# DEBUGSS_WRAP0_CSCTI1 register map
Vendor: Texas Instruments
Peripheral module from a debugger description file (folder am62P).
Registers are 32-bit, access per field, reset 0x0 unless marked. A register's access mark holds for its fields unless they carry their own. Offsets are as the file gives them; lines under a group give offsets from that group; [hi:lo] are bit positions; {n}, {i} and the like mark numbered series; 'fields as' and 'values as' point back to an identical list; <NAME> marks a mode.

## DEBUGSS_WRAP0_CSCTI1
0x00 CSCTI_CFG_1_CTICONTROL — CTI Control Register.
  [0] GLBEN rw — Enables or disables the Embedded Cross Trigger, 1=enabled
0x10 CSCTI_CFG_1_CTIINTACK — CTI Interrupt Acknowledge Register.
  [7:0] INTACK rw — Acknowledges the corresponding CTITRIGOUT output Write 1 = CTITRIGOUT is acknowledged and is cleared when MAPTRIGOUT is LOW There is one bit of the register for each CTITRIGOUT output
0x14 CSCTI_CFG_1_CTIAPPSET — CTI Application Trigger Set Register.
  [3:0] APPSET rw — The CTI Application Trigger Set Register is read/write A write to this register causes a channel event to be raised, corresponding to the bit written to
0x18 CSCTI_CFG_1_CTIAPPCLEAR — CTI Application Trigger Clear Register.
  [3:0] APPCLR rw — The CTI Application Trigger Clear Register is write-only A write to this register causes a channel event to be cleared, corresponding to the bit written to
0x1C CSCTI_CFG_1_CTIAPPPULSE — CTI Application Trigger Pulse Register.
  [3:0] APPPULSE rw — The CTI Application Pulse Register is write-only A write to this register causes a channel event pulse, one CTICLK period, to be generated, corresponding to the bit written to This register clears itself immediately
0x20 CSCTI_CFG_1_CTIINEN0 — CTI Application Trigger to Channel Enable Register 0
  [3:0] TRIGINEN rw — The CTI Trigger to Channel Enable Registers enable the signalling of an event on CTM channels when the core issues a trigger, CTITRIGIN, to the CTI There is one register for each of the eight CTITRIGIN inputs Within each register there is one bit for each of the four channels implemented These registers do not affect the application trigger operations
0x24 CSCTI_CFG_1_CTIINEN1 — CTI Application Trigger to Channel Enable Register 1
  [2:0] TRIGINEN rw — The CTI Trigger to Channel Enable Registers enable the signalling of an event on CTM channels when the core issues a trigger, CTITRIGIN, to the CTI There is one register for each of the eight CTITRIGIN inputs Within each register there is one bit for each of the four channels implemented These registers do not affect the application trigger operations
{0x20+4i} CSCTI_CFG_1_CTIINEN{i} (i=2..7) — CTI Application Trigger to Channel Enable Register {i}
  fields as CSCTI_CFG_1_CTIINEN0
{0xA0+4i} CSCTI_CFG_1_CTIOUTEN{i} (i=0..7) — CTI Channel to Trigger Enable Register {i}
  [3:0] TRIGOUTEN rw — The CTI Channel to Trigger Enable Registers define which channels can generate a CTITRIGOUT output There is one register for each of the eight CTITRIGOUT outputs Within each register there is one bit for each of the four channels implemented These registers affect the mapping from application trigger to trigger outputs
0x130 CSCTI_CFG_1_CTITRIGINSTATUS ro — CTI Trigger In Status Register
  [7:0] TRIGINSTATUS — Shows the status of the CTITRIGIN inputs: 1=CTITRIGIN is active, 0=CTITRIGIN is inactive
0x134 CSCTI_CFG_1_CTITRIGOUTSTATUS ro — CTI Trigger Out Status Register
  [7:0] TRIGOUTSTATUS — Shows the status of the CTITRIGOUT outputs: 1=CTITRIGOUT is active, 0=CTITRIGOUT is inactive
0x138 CSCTI_CFG_1_CTICHINSTATUS ro — CTI Channel In Status Register
  [3:0] CHINSTATUS — Shows the status of the CTICHIN inputs: 1=CTICHIN is active, 0=CTICHIN is inactive
0x13C CSCTI_CFG_1_CTICHOUTSTATUS ro — CTI Channel Out Status Register
  [3:0] CHOUTSTATUS — Shows the status of the CTICHOUT outputs: 1=CTICHOUT is active, 0=CTICHOUT is inactive
0x140 CSCTI_CFG_1_CTIGATE ro — The Gate Enable Register prevents the channels from propagating through the CTM to other CTIs.
  [3:0] CTIGATEEN — Gate enable for the four channels [1 per bit]
0x144 CSCTI_CFG_1_ASICCTL — Allows external multiplexing of the trigger signals
  [7:0] ASICCTL rw — Implementation-defined ASIC control, value written to the register is output on ASICCTL[7:0]
0xEDC CSCTI_CFG_1_ITCHINACK — Integration and Test register
  [3:0] CTCHINACK rw — Sets the value of the CTCHINACK outputs
0xEE0 CSCTI_CFG_1_ITTRIGINACK — ITTRIGINACK Register
  [7:0] CTTRIGINACK rw — Sets the value of the CTTRIGINACK outputs
0xEE4 CSCTI_CFG_1_ITCHOUT — ITCHOUT Register
  [3:0] CTCHOUT rw — Sets the value of the CTCHOUT outputs
0xEE8 CSCTI_CFG_1_ITTRIGOUT — ITTRIGOUT Register
  [7:0] CTTRIGOUT rw — Sets the value of the CTTRIGOUT outputs
0xEEC CSCTI_CFG_1_ITCHOUTACK — ITCHOUTACK Register
  [7:0] CTCHOUTACK rw — Sets the value of the CTCHOUTACK outputs
0xEF0 CSCTI_CFG_1_ITTRIGOUTACK ro — ITTRIGOUTACK Register
  [7:0] CTTRIGOUTACK — Reads the value of the CTTRIGOUTACK inputs
0xEF4 CSCTI_CFG_1_ITCHIN ro — ITCHIN Register
  [3:0] CTCHIN — Reads the value of the CTCHIN inputs
0xEF8 CSCTI_CFG_1_ITTRIGIN ro — ITTRIGIN Register
  [7:0] CTTRIGIN — Reads the value of the CTTRIGIN inputs
0xF00 CSCTI_CFG_1_ITCTRL — ITCTRL Register
  [0] ITEN rw — Integration Test control enable
0xFA0 CSCTI_CFG_1_CTSET — Claim Tag Set Register
  [3:0] CLAIM_TAG_SET rw
0xFA4 CSCTI_CFG_1_CTCLR — Claim Tag Clear Register
  [3:0] CLAIM_TAG_CLEAR rw
0xFB0 CSCTI_CFG_1_LAREG rw — Software must write 0xC5ACCE55 to this register in order for application to gain access to the other registers. If paddrdbg31 is high, this is ignored.
  [31:0] LOCKACCESSREG — Software must write 0xC5ACCE55 to this register in order for application to gain access to the other registers If paddrdbg31 is high, this is ignored
0xFB4 CSCTI_CFG_1_LSREG ro — The CTI implements two memory maps controlled through PADDRDBG31. When PADDRDBG31 is HIGH, the Lock Status Register reads as 0x0 indicating that no lock exists. When PADDRDBG31 is LOW, the Lock Status Register reads as 0x3 from reset. This indicates a 32-bit lock access mechanism is present and is locked
  [1:0] LOCK_STATUS — The CTI implements two memory maps controlled through PADDRDBG31 When PADDRDBG31 is HIGH, the Lock Status Register reads as 0x0 indicating that no lock exists When PADDRDBG31 is LOW, the Lock Status Register reads as 0x3 from reset This indicates a 32-bit lock access mechanism is present and is locked Application must write to the LAREG to gain access
0xFB8 CSCTI_CFG_1_AUTHST ro — Reports the required security level.
  [3:0] AUTHENTICATION_STATUS — Reports the required security level bit 0 indicates Invasive Debug Controlled and bit 1 is the current value Bit 2 indicates non-invasive debug controlled and bit 3 is the current value Returns 0x5
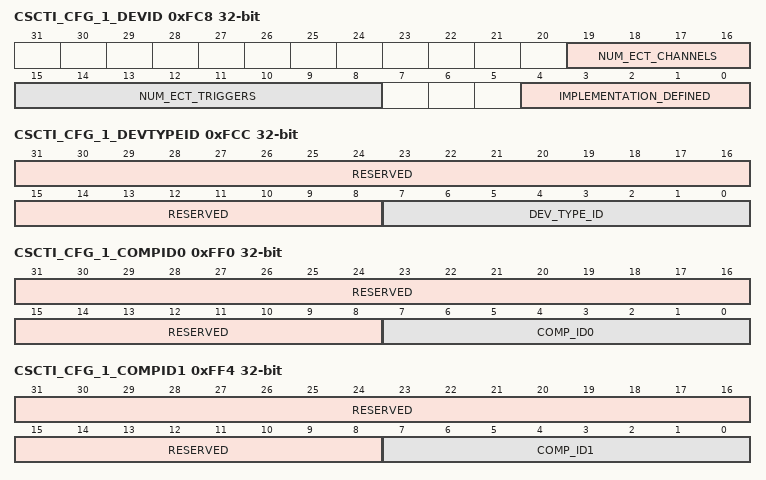
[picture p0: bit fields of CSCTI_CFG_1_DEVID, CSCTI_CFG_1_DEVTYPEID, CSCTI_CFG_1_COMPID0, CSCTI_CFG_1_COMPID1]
0xFC8 CSCTI_CFG_1_DEVID ro — Device ID Register
  [19:16] NUM_ECT_CHANNELS — Number of ECT Channels available
  [15:8] NUM_ECT_TRIGGERS — Number of ECT trigger available
  [4:0] IMPLEMENTATION_DEFINED — Indicates the number of multiplexing available on Trigger Inputs and Outputs using ASICCTL Defailt value of 0 indicates no multiplexing present
0xFCC CSCTI_CFG_1_DEVTYPEID ro — Device Type Identifier Register
  [31:8] RESERVED — Reserveed, returns 0
  [7:0] DEV_TYPE_ID — Device Type Identifier
0xFD0 CSCTI_CFG_1_PERID4 ro — Peripheral ID4 Register
  [7:0] PERIPH_ID4 — Peripheral ID 4, returns 0x4
0xFE0 CSCTI_CFG_1_PERID0 ro — Peripheral ID0 Register
  [7:0] PERIPH_ID0 — Perpiheral ID 0, returns 0x06
0xFE4 CSCTI_CFG_1_PERID1 ro — Peripheral ID1 Register
  [7:0] PERIPH_ID1 — Peripheral ID 1, returns 0xB9
0xFE8 CSCTI_CFG_1_PERID2 ro — Peripheral ID2 Register
  [7:0] PERIPH_ID2 — Peripheral ID 2, returns 9x2B
0xFEC CSCTI_CFG_1_PERID3 ro — Peripheral ID3 Register
  [7:0] PERPIH_ID3 — Peripheral ID3 register, returns 0x00
0xFF0 CSCTI_CFG_1_COMPID0 ro — Component ID0 Register
  [31:8] RESERVED — Read returns 0
  [7:0] COMP_ID0 — A component identification register, that indicates that the identification registers are present This register also indicates the component class
0xFF4 CSCTI_CFG_1_COMPID1 ro — Component ID1 Register
  [31:8] RESERVED — Read returns 0
  [7:0] COMP_ID1 — A component identification register, that indicates that the identification registers are present This register also indicates the component class
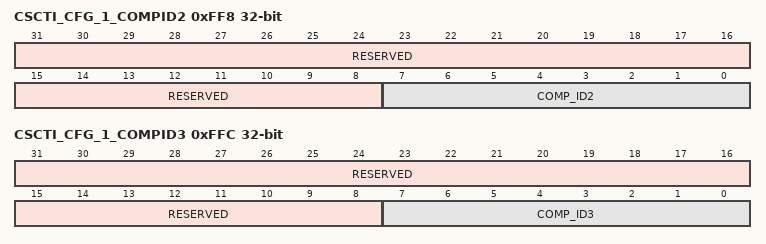
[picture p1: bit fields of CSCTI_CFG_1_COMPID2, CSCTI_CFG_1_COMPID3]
0xFF8 CSCTI_CFG_1_COMPID2 ro — Component ID2 Register
  [31:8] RESERVED — Returns 0
  [7:0] COMP_ID2 — A component identification register, that indicates that the identification registers are present This register also indicates the component class
0xFFC CSCTI_CFG_1_COMPID3 ro — Component ID3 Register
  [31:8] RESERVED — returns 0 when read
  [7:0] COMP_ID3 — A component identification register, that indicates that the identification registers are present This register also indicates the component class
